# STM32F100xE register map
File version: 1.0
Registers are 32-bit, read-write, reset 0x0 unless marked. A register's access mark holds for its fields unless they carry their own. Offsets are from the block's base; [hi:lo] are bit positions; {n}, {i} and the like mark numbered series.

## CEC — Consumer Electronics Control (CEC)
Base 0x40007800
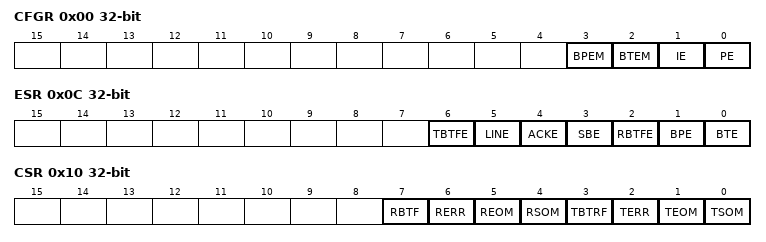
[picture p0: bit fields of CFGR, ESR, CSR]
0x00 CFGR
  [3] BPEM — Bit Period Error Mode
  [2] BTEM — Bit Timing Error Mode
  [1] IE — Interrupt Enable
  [0] PE — Peripheral Enable
0x04 OAR
  [3:0] OA — OA[3:0]: Own Address
0x08 PRES
  [13:0] PRES — Prescaler Counter Value
0x0C ESR
  [6] TBTFE — Tx Block Transfer Finished Error
  [5] LINE — Line Error
  [4] ACKE — Block Acknowledge Error
  [3] SBE — Start Bit Error
  [2] RBTFE — Rx Block Transfer Finished Error
  [1] BPE — Bit Period Error
  [0] BTE — Bit Timing Error
0x10 CSR
  [7] RBTF — Rx Block Transfer Finished
  [6] RERR — Rx Error
  [5] REOM — Rx End Of Message
  [4] RSOM — Rx Start Of Message
  [3] TBTRF — Tx Byte Transfer Request or Block Transfer Finished
  [2] TERR — Tx Error
  [1] TEOM — Tx End Of Message
  [0] TSOM — Tx Start Of Message
0x14 TXD
  [7:0] TXD — Tx Data register
0x18 RXD
  [7:0] RXD — Rx Data register

## AFIO — Alternate Function I/O
Base 0x40010000
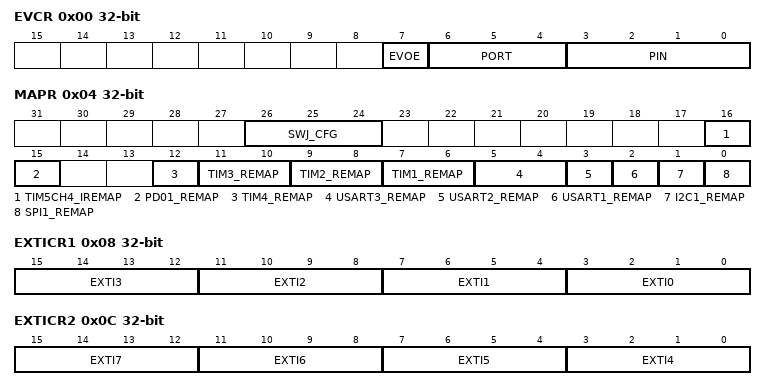
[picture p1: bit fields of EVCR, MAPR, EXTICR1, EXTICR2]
0x00 EVCR
  [7] EVOE — Event Output Enable
  [6:4] PORT — PORT[2:0] bits (Port selection)
  [3:0] PIN — PIN[3:0] bits (Pin selection)
0x04 MAPR
  [26:24] SWJ_CFG — SWJ_CFG[2:0] bits (Serial Wire JTAG configuration)
  [16] TIM5CH4_IREMAP — TIM5 Channel4 Internal Remap
  [15] PD01_REMAP — Port D0/Port D1 mapping on OSC_IN/OSC_OUT
  [12] TIM4_REMAP — TIM4_REMAP bit (TIM4 remapping)
  [11:10] TIM3_REMAP — TIM3_REMAP[1:0] bits (TIM3 remapping)
  [9:8] TIM2_REMAP — TIM2_REMAP[1:0] bits (TIM2 remapping)
  [7:6] TIM1_REMAP — TIM1_REMAP[1:0] bits (TIM1 remapping)
  [5:4] USART3_REMAP — USART3_REMAP[1:0] bits (USART3 remapping)
  [3] USART2_REMAP — USART2 remapping
  [2] USART1_REMAP — USART1 remapping
  [1] I2C1_REMAP — I2C1 remapping
  [0] SPI1_REMAP — SPI1 remapping
0x08 EXTICR1
  [4n+3:4n] EXTI{n} (n=0..3) — EXTI {n} configuration
0x0C EXTICR2
  [4n-13:4n-16] EXTI{n} (n=4..7) — EXTI {n} configuration
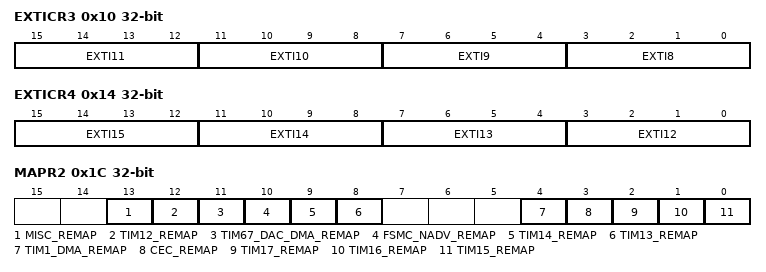
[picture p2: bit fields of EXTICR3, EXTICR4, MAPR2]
0x10 EXTICR3
  [4n-29:4n-32] EXTI{n} (n=8..11) — EXTI {n} configuration
0x14 EXTICR4
  [4n-45:4n-48] EXTI{n} (n=12..15) — EXTI {n} configuration
0x1C MAPR2
  [13] MISC_REMAP — Miscellaneous remapping
  [12] TIM12_REMAP — TIM12 remapping
  [11] TIM67_DAC_DMA_REMAP — TIM6/TIM7 and DAC DMA remapping
  [10] FSMC_NADV_REMAP — FSMC NADV remapping
  [9] TIM14_REMAP — TIM14 remapping
  [8] TIM13_REMAP — TIM13 remapping
  [4] TIM1_DMA_REMAP — TIM1_DMA remapping
  [3] CEC_REMAP — CEC remapping
  [2] TIM17_REMAP — TIM17 remapping
  [1] TIM16_REMAP — TIM16 remapping
  [0] TIM15_REMAP — TIM15 remapping

## EXTI — External Interrupt/Event Controller
Base 0x40010400
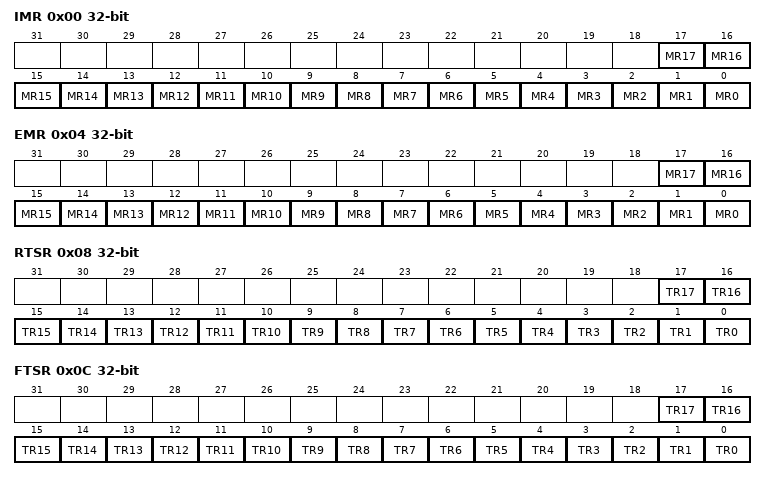
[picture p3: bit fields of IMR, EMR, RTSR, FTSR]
0x00 IMR
  [n] MR{n} (n=0..17) — Interrupt Mask on line {n}
0x04 EMR
  [n] MR{n} (n=0..17) — Event Mask on line {n}
0x08 RTSR
  [n] TR{n} (n=0..17) — Rising trigger event configuration bit of line {n}
0x0C FTSR
  [n] TR{n} (n=0..17) — Falling trigger event configuration bit of line {n}
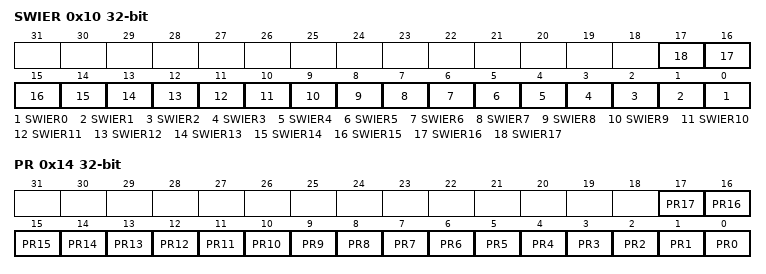
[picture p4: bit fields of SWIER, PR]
0x10 SWIER
  [n] SWIER{n} (n=0..17) — Software Interrupt on line {n}
0x14 PR
  [n] PR{n} (n=0..17) — Pending bit for line {n}

## GPIOA — General Purpose I/O
Base 0x40010800
Same registers: GPIOB 0x40010C00, GPIOC 0x40011000, GPIOD 0x40011400, GPIOE 0x40011800, GPIOF 0x40011C00, GPIOG 0x40012000
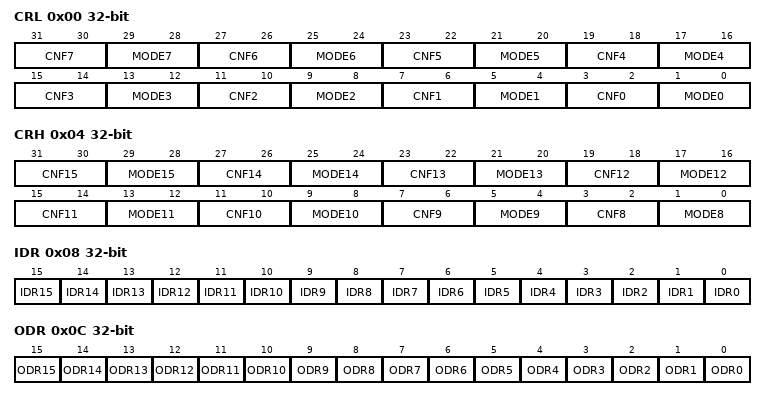
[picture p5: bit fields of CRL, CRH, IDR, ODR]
0x00 CRL
  [4n+3:4n+2] CNF{n} (n=0..7) — CNF{n}[1:0] bits (Port x configuration bits, pin {n})
  [4n+1:4n] MODE{n} (n=0..7) — MODE{n}[1:0] bits (Port x mode bits, pin {n})
0x04 CRH
  [4n-29:4n-30] CNF{n} (n=8..15) — CNF{n}[1:0] bits (Port x configuration bits, pin {n})
  [4n-31:4n-32] MODE{n} (n=8..15) — MODE{n}[1:0] bits (Port x mode bits, pin {n})
0x08 IDR
  [n] IDR{n} (n=0..15) — Port input data, bit {n}
0x0C ODR
  [n] ODR{n} (n=0..15) — Port output data, bit {n}
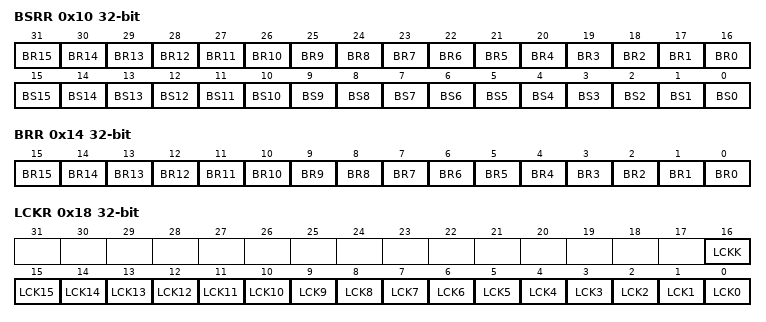
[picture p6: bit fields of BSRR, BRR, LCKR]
0x10 BSRR
  [n+16] BR{n} (n=0..15) — Port x Reset bit {n}
  [n] BS{n} (n=0..15) — Port x Set bit {n}
0x14 BRR
  [n] BR{n} (n=0..15) — Port x Reset bit {n}
0x18 LCKR
  [16] LCKK — Lock key
  [n] LCK{n} (n=0..15) — Port x Lock bit {n}
